# ICSSM_ICSSM_PR1_MII_RT_PR1_MII_RT_CFG_48032000h register map
Vendor: Texas Instruments
Peripheral module from a debugger description file (folder AM263X).
Registers are 32-bit, read-write, reset values left out (the file's numbers can be read two ways) unless marked. A register's access mark holds for its fields unless they carry their own. Offsets are as the file gives them; lines under a group give offsets from that group; [hi:lo] are bit positions; {n}, {i} and the like mark numbered series; 'fields as' and 'values as' point back to an identical list; <NAME> marks a mode.

## ICSSM_PR1_MII_RT_PR1_MII_RT_CFG
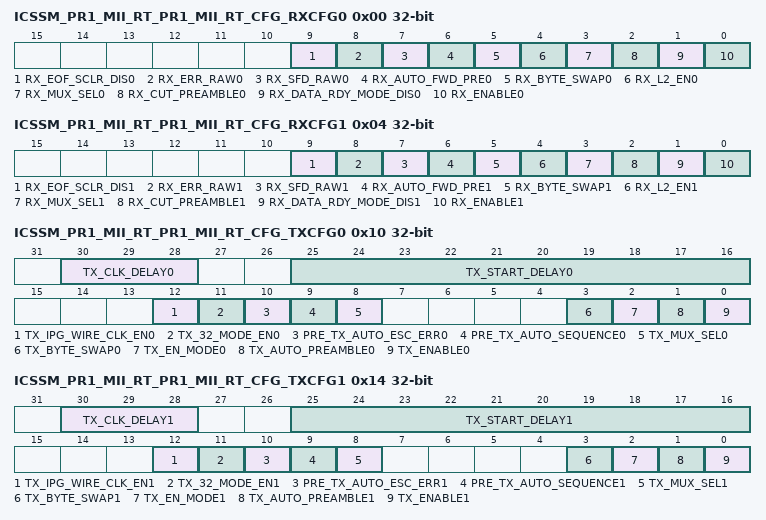
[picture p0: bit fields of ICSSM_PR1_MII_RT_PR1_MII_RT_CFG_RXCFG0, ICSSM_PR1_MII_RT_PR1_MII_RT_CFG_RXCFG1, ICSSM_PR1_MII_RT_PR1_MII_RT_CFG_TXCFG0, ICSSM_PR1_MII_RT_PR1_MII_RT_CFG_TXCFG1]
0x00 ICSSM_PR1_MII_RT_PR1_MII_RT_CFG_RXCFG0 — MIIRXCFG0Register.
  [9] RX_EOF_SCLR_DIS0, [8] RX_ERR_RAW0, [7] RX_SFD_RAW0, [6] RX_AUTO_FWD_PRE0, [5] RX_BYTE_SWAP0, [4] RX_L2_EN0, [3] RX_MUX_SEL0, [2] RX_CUT_PREAMBLE0, [1] RX_DATA_RDY_MODE_DIS0, [0] RX_ENABLE0
0x04 ICSSM_PR1_MII_RT_PR1_MII_RT_CFG_RXCFG1 — MIIRXCFG1Register.
  [9] RX_EOF_SCLR_DIS1, [8] RX_ERR_RAW1, [7] RX_SFD_RAW1, [6] RX_AUTO_FWD_PRE1, [5] RX_BYTE_SWAP1, [4] RX_L2_EN1, [3] RX_MUX_SEL1, [2] RX_CUT_PREAMBLE1, [1] RX_DATA_RDY_MODE_DIS1, [0] RX_ENABLE1
0x10 ICSSM_PR1_MII_RT_PR1_MII_RT_CFG_TXCFG0 — MIITXCFG0Register.
  [30:28] TX_CLK_DELAY0, [25:16] TX_START_DELAY0, [12] TX_IPG_WIRE_CLK_EN0, [11] TX_32_MODE_EN0, [10] PRE_TX_AUTO_ESC_ERR0, [9] PRE_TX_AUTO_SEQUENCE0, [8] TX_MUX_SEL0, [3] TX_BYTE_SWAP0, [2] TX_EN_MODE0, [1] TX_AUTO_PREAMBLE0, [0] TX_ENABLE0
0x14 ICSSM_PR1_MII_RT_PR1_MII_RT_CFG_TXCFG1 — MIITXCFG1Register.
  [30:28] TX_CLK_DELAY1, [25:16] TX_START_DELAY1, [12] TX_IPG_WIRE_CLK_EN1, [11] TX_32_MODE_EN1, [10] PRE_TX_AUTO_ESC_ERR1, [9] PRE_TX_AUTO_SEQUENCE1, [8] TX_MUX_SEL1, [3] TX_BYTE_SWAP1, [2] TX_EN_MODE1, [1] TX_AUTO_PREAMBLE1, [0] TX_ENABLE1
0x20 ICSSM_PR1_MII_RT_PR1_MII_RT_CFG_TX_CRC0 ro — MIITXCRC0Register.
  [31:0] TX_CRC0 — Transmit CRC for last packet
0x24 ICSSM_PR1_MII_RT_PR1_MII_RT_CFG_TX_CRC1 ro — MIITXCRC1Register.
  [31:0] TX_CRC1 — Transmit CRC for last packet
0x30 ICSSM_PR1_MII_RT_PR1_MII_RT_CFG_TX_IPG0 — MIITXIPG0Register.
  [15:0] TX_IPG0 — Transmit IPG
0x34 ICSSM_PR1_MII_RT_PR1_MII_RT_CFG_TX_IPG1 — MIITXIPG1Register.
  [15:0] TX_IPG1 — Transmit IPG
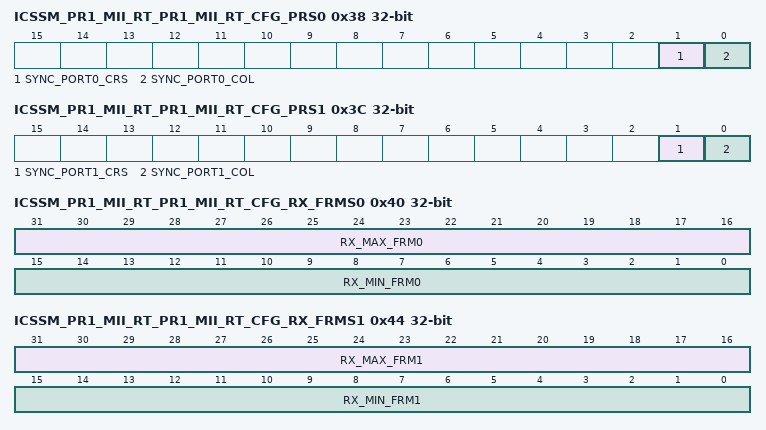
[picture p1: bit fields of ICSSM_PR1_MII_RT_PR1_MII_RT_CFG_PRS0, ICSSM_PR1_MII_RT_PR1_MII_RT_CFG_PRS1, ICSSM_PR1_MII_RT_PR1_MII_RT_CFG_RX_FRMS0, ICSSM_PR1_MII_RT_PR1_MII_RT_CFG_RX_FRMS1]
0x38 ICSSM_PR1_MII_RT_PR1_MII_RT_CFG_PRS0 ro — MIIPortStatus0Register.
  [1] SYNC_PORT0_CRS, [0] SYNC_PORT0_COL
0x3C ICSSM_PR1_MII_RT_PR1_MII_RT_CFG_PRS1 ro — MIIPortStatus1Register.
  [1] SYNC_PORT1_CRS, [0] SYNC_PORT1_COL
0x40 ICSSM_PR1_MII_RT_PR1_MII_RT_CFG_RX_FRMS0 — MIIRXFRMS0Register.
  [31:16] RX_MAX_FRM0, [15:0] RX_MIN_FRM0
0x44 ICSSM_PR1_MII_RT_PR1_MII_RT_CFG_RX_FRMS1 — MIIRXFRMS1Register.
  [31:16] RX_MAX_FRM1, [15:0] RX_MIN_FRM1
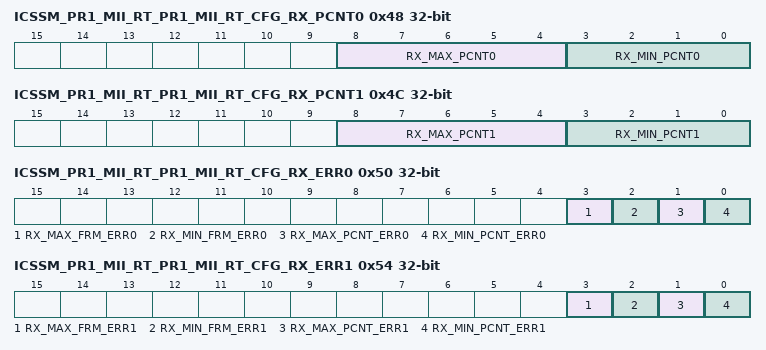
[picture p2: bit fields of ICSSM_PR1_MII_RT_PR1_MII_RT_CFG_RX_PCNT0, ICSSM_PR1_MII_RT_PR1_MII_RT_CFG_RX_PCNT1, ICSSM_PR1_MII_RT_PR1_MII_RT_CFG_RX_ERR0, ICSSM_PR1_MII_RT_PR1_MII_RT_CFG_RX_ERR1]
0x48 ICSSM_PR1_MII_RT_PR1_MII_RT_CFG_RX_PCNT0 — MIIRXPCNT0Register.
  [8:4] RX_MAX_PCNT0, [3:0] RX_MIN_PCNT0
0x4C ICSSM_PR1_MII_RT_PR1_MII_RT_CFG_RX_PCNT1 — MIIRXPCNT1Register.
  [8:4] RX_MAX_PCNT1, [3:0] RX_MIN_PCNT1
0x50 ICSSM_PR1_MII_RT_PR1_MII_RT_CFG_RX_ERR0 access not given — MIIRXERR0Register.
  [3] RX_MAX_FRM_ERR0 — Rx_max_frm_err0 (access R/W1C)
  [2] RX_MIN_FRM_ERR0 — Rx_min_frm_err0 (access R/W1C)
  [1] RX_MAX_PCNT_ERR0 — Rx_max_pcnt_err0 (access R/W1C)
  [0] RX_MIN_PCNT_ERR0 — Rx_min_pcnt_err0 (access R/W1C)
0x54 ICSSM_PR1_MII_RT_PR1_MII_RT_CFG_RX_ERR1 access not given — MIIRXERR1Register.
  [3] RX_MAX_FRM_ERR1 — Rx_max_frm_err1 (access R/W1C)
  [2] RX_MIN_FRM_ERR1 — Rx_min_frm_err1 (access R/W1C)
  [1] RX_MAX_PCNT_ERR1 — Rx_max_pcnt_err1 (access R/W1C)
  [0] RX_MIN_PCNT_ERR1 — Rx_min_pcnt_err1 (access R/W1C)
0x60 ICSSM_PR1_MII_RT_PR1_MII_RT_CFG_RX_FIFO_LEVEL0 ro — MIIRXFIFOLEVEL0Register.
  [7:0] RX_FIFO_LEVEL0
0x64 ICSSM_PR1_MII_RT_PR1_MII_RT_CFG_RX_FIFO_LEVEL1 ro — MIIRXFIFOLEVEL1Register.
  [7:0] RX_FIFO_LEVEL1
0x68 ICSSM_PR1_MII_RT_PR1_MII_RT_CFG_TX_FIFO_LEVEL0 ro — MIIRXFIFOLEVEL0Register.
  [7:0] TX_FIFO_LEVEL0
0x6C ICSSM_PR1_MII_RT_PR1_MII_RT_CFG_TX_FIFO_LEVEL1 ro — MIIRXFIFOLEVEL1Register.
  [7:0] TX_FIFO_LEVEL1
